# A31G22x register map
Vendor: ABOV Semiconductor Co., Ltd.; Series: A31G22x; File version: 0.2
CPU: CM0PLUS r0p1, little endian, no MPU, no FPU, VTOR, 2 interrupt priority bits
Registers are 32-bit, read-write, reset 0x0 unless marked. A register's access mark holds for its fields unless they carry their own. Offsets are from the block's base; [hi:lo] are bit positions.

## CMP — COMPARATOR
Base 0x40003420
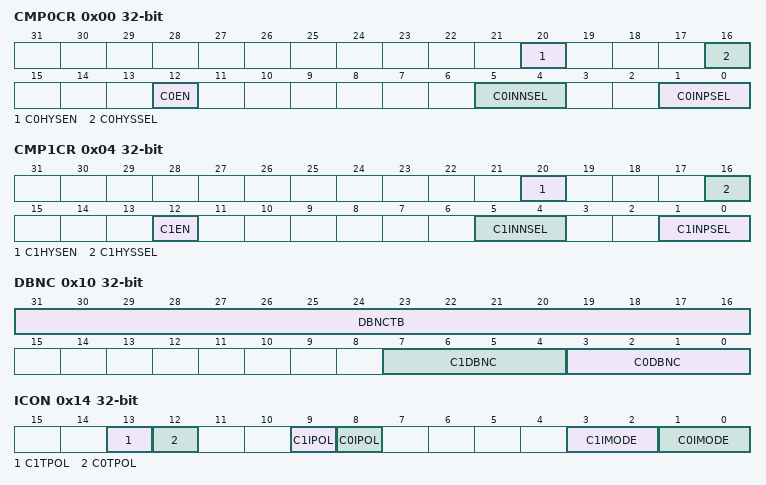
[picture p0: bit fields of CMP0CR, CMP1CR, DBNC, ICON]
0x00 CMP0CR — Comparator 0 Control Register
  [20] C0HYSEN — Comparator 0 Hysteresis Enable 0: Disable Hysteresis 1: Enable Hysteresis
  [16] C0HYSSEL — Comparator 0 Hysteresis Select 0: 5mV Hysteresis 1: 20mV Hysteresis
  [12] C0EN — Comparator 0 Enable bits 0: Disable Comparator 1: Enable Comparator
  [5:4] C0INNSEL — Comparator 0 Reference (input -) Selection bit 00: CREF0 (PA7) 01: BGR 10: DAC Output 11: Reserved
  [1:0] C0INPSEL — Comparator 0 Source (input +) Selection bit 00: CP0 (PA2) 01: GND 10: GND 11: GND
0x04 CMP1CR — Comparator 1 Control Register
  [20] C1HYSEN — Comparator 1 Hysteresis Enable 0: Disable Hysteresis 1: Enable Hysteresis
  [16] C1HYSSEL — Comparator 1 Hysteresis Select 0: 5mV Hysteresis 1: 20mV Hysteresis
  [12] C1EN — Comparator 1 Enable bits 0: Disable Comparator 1: Enable Comparator
  [5:4] C1INNSEL — Comparator Reference (input -) Selection bit 00: CREF1 (PA6) 01: BGR 10: DAC Output 11: Reserved
  [1:0] C1INPSEL — Comparator Source (input +) Selection bit 00: CP1A (PA5) 01: CP1B (PA4) 10: CP1C (PA3) 11: GND
0x10 DBNC — Comparator Debounce Register
  [31:16] DBNCTB — Debounce time base counter System clock/(DBNCTB *2) becomes shift clock of debounce logic When DBNCTB is 0, system clock would be debounce clock.
  [7:4] C1DBNC — Debounce shift Selection When it is 0x0, debounce function is disable Shift number of debounce logic is (C1DBNC + 1) when C1DBNC is more than 1
  [3:0] C0DBNC — Debounce shift Selection When it is 0x0, debounce function is disable Shift number of debounce logic is (C1DBNC + 1) when C1DBNC is more than 1
0x14 ICON — Comparator Interrupt Control Register
  [13] C1TPOL — Comparator 1 Trigger output polarity(to trigger other IP) 0: output normal (comparator out high activates trigger) 1: output inverted (XOR)
  [12] C0TPOL — Comparator 0 Trigger output polarity(to trigger other IP) 0: output normal (comparator out high activates trigger) 1: output inverted (XOR)
  [9] C1IPOL — Comparator 1 interrupt polarity (level mode) 0: interrupt at comparator out high 1: interrupt at comparator out low
  [8] C0IPOL — Comparator 0 interrupt polarity (level mode) 0: interrupt at comparator out high 1: interrupt at comparator out low
  [3:2] C1IMODE — Comparator 1 Interrupt Mode 00: level interrupt (by IPOL1) 01: rising edge interrupt 10: falling edge interrupt 11: both edge interrupt
  [1:0] C0IMODE — Comparator 0 Interrupt Mode 00: level interrupt (by IPOL0) 01: rising edge interrupt 10: falling edge interrupt 11: both edge interrupt
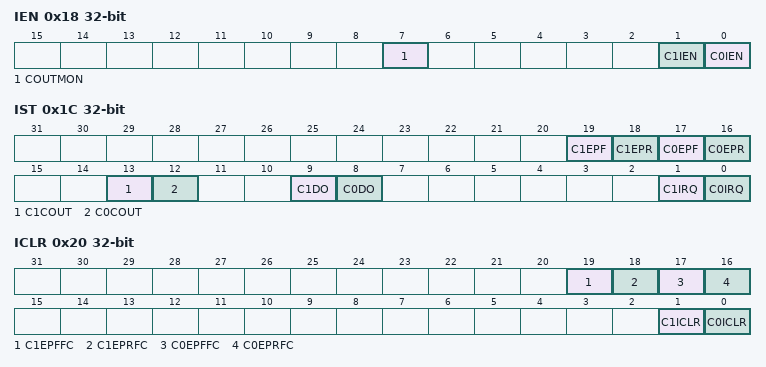
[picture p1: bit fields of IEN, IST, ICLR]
0x18 IEN — Comparator Interrupt Enable Register
  [7] COUTMON — Enable Comparator output monitoring 0: Disable 1: Enable
  [1] C1IEN — Comparator 1 Interrupt Enable 0: Disable 1: Enable
  [0] C0IEN — Comparator 0 Interrupt Enable 0: Disable 1: Enable
0x1C IST ro — Comparator Interrupt Status Register
  [19] C1EPF — The falling edge polarity status flag of comparator 1 0: None 1: Comparator 1 edge polarity is falling
  [18] C1EPR — The rising edge polarity status flag of comparator 1 0: None 1: Comparator 1 edge polarity is rising
  [17] C0EPF — The falling edge polarity status flag of comparator 0 0: None 1: Comparator 0 edge polarity is falling
  [16] C0EPR — The rising edge polarity status flag of comparator 0 0: None 1: Comparator 0 edge polarity is rising
  [13] C1COUT — Comparator 1 current output status 0: Current output is low 1: current output is high
  [12] C0COUT — Comparator 0 current output status 0: Current output is low 1: current output is high
  [9] C1DO — Comparator 1 debounce output status 0: None 1: Debounced output
  [8] C0DO — Comparator 0 debounce output status 0: None 1: Debounced output
  [1] C1IRQ — Comparator 1 interrupt Status 0: No Comparator Interrupt 1: Comparator Interrupt asserted
  [0] C0IRQ — Comparator 0 interrupt Status 0: No Comparator Interrupt 1: Comparator Interrupt asserted
0x20 ICLR — Comparator Interrupt Clear Register
  [19] C1EPFFC wo — Comparator 1 Edge Polarity Falling Flag Clear (write "1" to clear C1EPFFC)
  [18] C1EPRFC wo — Comparator 1 Edge Polarity Rising Flag Clear (write "1" to clear C1EPRFC)
  [17] C0EPFFC wo — Comparator 0 Edge Polarity Falling Flag Clear (write "1" to clear C0EPFFC)
  [16] C0EPRFC wo — Comparator 0 Edge Polarity Rising Flag Clear (write "1" to clear C0EPRFC)
  [1] C1ICLR — Comparator 1 Interrupt Clear (write "1" to clear C1IRQ)
  [0] C0ICLR — Comparator 0 Interrupt Clear (write "1" to clear C0IRQ)
